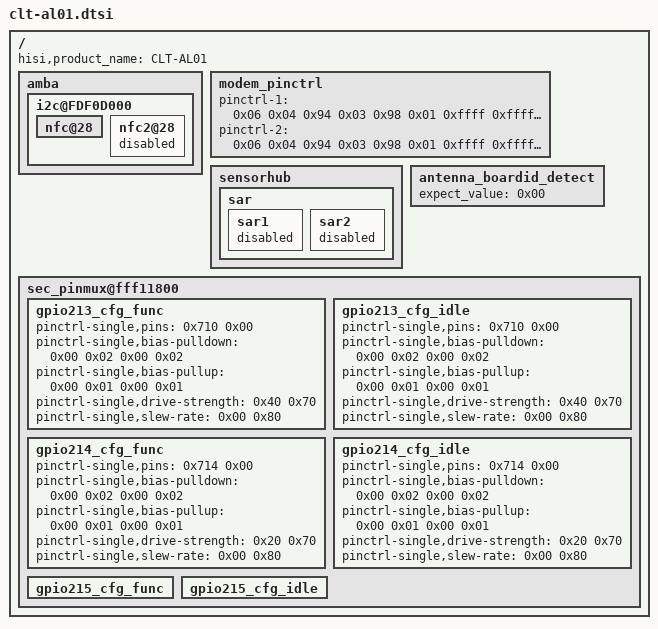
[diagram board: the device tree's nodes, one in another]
/include/ "../clt-common.dtsi"

/ {
	hisi,product_name = "CLT-AL01";

	amba {
		i2c@FDF0D000 {
			nfc@28 {
				status = "ok";
			};

			nfc2@28 {
				status = "disabled";
			};
		};
	};

	modem_pinctrl {
		pinctrl-1 = <0x06 0x04 0x94 0x03 0x98 0x01 0xffff 0xffff 0x06 0x05 0x98 0x03 0x9c 0x00 0xffff 0xffff 0x07 0x02 0xac 0x02 0xb0 0x00 0xffff 0xffff 0x07 0x03 0xb0 0x01 0xb4 0x00 0x01 0x00 0x07 0x04 0xb4 0x01 0xb8 0x00 0x01 0x00 0x07 0x05 0xb8 0x01 0xbc 0x00 0x01 0x00 0x07 0x06 0xbc 0x01 0xc0 0x00 0x01 0x00 0x07 0x07 0xc0 0x01 0xc4 0x00 0x01 0x00 0x08 0x00 0xc4 0xffff 0xc8 0xffff 0xffff 0xffff 0x08 0x01 0xc8 0xffff 0xcc 0xffff 0xffff 0xffff 0x08 0x02 0xcc 0x01 0xd0 0x00 0x01 0x00 0x08 0x03 0xd0 0x01 0xd4 0x00 0x01 0x00 0x08 0x04 0xd4 0x01 0xd8 0x00 0x01 0x00 0x08 0x05 0xd8 0x01 0xdc 0x00 0x01 0x00 0x08 0x06 0xdc 0x01 0xe0 0x00 0x01 0x00 0x08 0x07 0xe0 0x01 0xe4 0x00 0x01 0x00 0x09 0x00 0xe4 0x01 0xe8 0x00 0x01 0x00 0x09 0x01 0xe8 0x01 0xec 0x00 0x01 0x00 0x09 0x02 0xec 0x01 0xf0 0x00 0x01 0x00 0x09 0x03 0xf0 0x01 0xf4 0x00 0x01 0x00 0x09 0x04 0xf4 0x01 0xf8 0x00 0x01 0x00 0x09 0x05 0xf8 0x01 0xfc 0x00 0x01 0x00 0x09 0x06 0xfc 0x01 0x100 0x00 0x01 0x00 0x09 0x07 0x100 0x01 0x104 0x00 0x01 0x00 0x0a 0x00 0x104 0x01 0x108 0x00 0x01 0x00 0x0a 0x01 0x108 0x01 0x10c 0x00 0x01 0x00 0x0a 0x02 0x10c 0x03 0x110 0x00 0xffff 0xffff 0x0a 0x03 0x110 0x03 0x114 0x02 0xffff 0xffff 0x0a 0x04 0x114 0x01 0x118 0x00 0x01 0x00 0x0a 0x05 0x118 0x01 0x11c 0x00 0x01 0x00 0x0a 0x06 0x11c 0x01 0x120 0x00 0x01 0x00 0x0a 0x07 0x120 0x01 0x124 0x00 0x01 0x00 0x0b 0x00 0x124 0x01 0x128 0x00 0xffff 0xffff 0x0b 0x01 0x128 0x01 0x12c 0x02 0xffff 0xffff 0x0b 0x02 0x12c 0x01 0x130 0x00 0xffff 0xffff 0x0b 0x03 0x130 0x01 0x134 0x02 0xffff 0xffff 0x0b 0x04 0x134 0x01 0x138 0x00 0xffff 0xffff 0x0b 0x05 0x138 0x01 0x13c 0x02 0xffff 0xffff 0x0b 0x06 0x13c 0x01 0x140 0x00 0xffff 0xffff 0x0b 0x07 0x140 0x01 0x144 0x02 0xffff 0xffff 0x0c 0x00 0x144 0x01 0x148 0x00 0xffff 0xffff 0x12 0x05 0xac 0x03 0xdc 0x00 0xffff 0xffff 0x18 0x05 0x4c 0xffff 0x78 0xffff 0x00 0xffff>;
		pinctrl-2 = <0x06 0x04 0x94 0x03 0x98 0x01 0xffff 0xffff 0x06 0x05 0x98 0x03 0x9c 0x00 0xffff 0xffff 0x07 0x02 0xac 0x02 0xb0 0x00 0xffff 0xffff 0x07 0x03 0xb0 0x00 0xb4 0x00 0x00 0x00 0x07 0x04 0xb4 0x00 0xb8 0x00 0x00 0x00 0x07 0x05 0xb8 0x00 0xbc 0x00 0x00 0x00 0x07 0x06 0xbc 0x00 0xc0 0x00 0x00 0x00 0x07 0x07 0xc0 0x00 0xc4 0x00 0x00 0x00 0x08 0x00 0xc4 0xffff 0xc8 0xffff 0xffff 0xffff 0x08 0x01 0xc8 0xffff 0xcc 0xffff 0xffff 0xffff 0x08 0x02 0xcc 0x00 0xd0 0x00 0x00 0x00 0x08 0x03 0xd0 0x00 0xd4 0x00 0x00 0x00 0x08 0x04 0xd4 0x00 0xd8 0x00 0x00 0x00 0x08 0x05 0xd8 0x00 0xdc 0x00 0x00 0x00 0x08 0x06 0xdc 0x00 0xe0 0x00 0x00 0x00 0x08 0x07 0xe0 0x00 0xe4 0x00 0x00 0x00 0x09 0x00 0xe4 0x00 0xe8 0x00 0x00 0x00 0x09 0x01 0xe8 0x00 0xec 0x00 0x00 0x00 0x09 0x02 0xec 0x00 0xf0 0x00 0x00 0x00 0x09 0x03 0xf0 0x00 0xf4 0x00 0x00 0x00 0x09 0x04 0xf4 0x00 0xf8 0x00 0x00 0x00 0x09 0x05 0xf8 0x00 0xfc 0x00 0x00 0x00 0x09 0x06 0xfc 0x00 0x100 0x00 0x00 0x00 0x09 0x07 0x100 0x00 0x104 0x00 0x00 0x00 0x0a 0x00 0x104 0x00 0x108 0x00 0x00 0x00 0x0a 0x01 0x108 0x00 0x10c 0x00 0x00 0x00 0x0a 0x02 0x10c 0x03 0x110 0x00 0xffff 0xffff 0x0a 0x03 0x110 0x03 0x114 0x02 0xffff 0xffff 0x0a 0x04 0x114 0x00 0x118 0x00 0x00 0x00 0x0a 0x05 0x118 0x00 0x11c 0x00 0x00 0x00 0x0a 0x06 0x11c 0x00 0x120 0x00 0x00 0x00 0x0a 0x07 0x120 0x00 0x124 0x00 0x00 0x00 0x0b 0x00 0x124 0x01 0x128 0x00 0xffff 0xffff 0x0b 0x01 0x128 0x01 0x12c 0x02 0xffff 0xffff 0x0b 0x02 0x12c 0x01 0x130 0x00 0xffff 0xffff 0x0b 0x03 0x130 0x01 0x134 0x02 0xffff 0xffff 0x0b 0x04 0x134 0x00 0x138 0x02 0x00 0xffff 0x0b 0x05 0x138 0x00 0x13c 0x02 0x00 0xffff 0x0b 0x06 0x13c 0x01 0x140 0x00 0xffff 0xffff 0x0b 0x07 0x140 0x01 0x144 0x02 0xffff 0xffff 0x0c 0x00 0x144 0x01 0x148 0x00 0xffff 0xffff 0x12 0x05 0xac 0x03 0xdc 0x00 0xffff 0xffff 0x18 0x05 0x4c 0xffff 0x78 0xffff 0xffff 0xffff>;
	};

	sensorhub {
		sar {
			sar1 {
				status = "disabled";
			};

			sar2 {
				status = "disabled";
			};
		};
	};

	antenna_boardid_detect {
		expect_value = <0x00>;
	};

	sec_pinmux@fff11800 {
		gpio213_cfg_func {
			pinctrl-single,pins = <0x710 0x00>;
			pinctrl-single,bias-pulldown = <0x00 0x02 0x00 0x02>;
			pinctrl-single,bias-pullup = <0x00 0x01 0x00 0x01>;
			pinctrl-single,drive-strength = <0x40 0x70>;
			pinctrl-single,slew-rate = <0x00 0x80>;
			phandle = <0x664>;
		};

		gpio213_cfg_idle {
			pinctrl-single,pins = <0x710 0x00>;
			pinctrl-single,bias-pulldown = <0x00 0x02 0x00 0x02>;
			pinctrl-single,bias-pullup = <0x00 0x01 0x00 0x01>;
			pinctrl-single,drive-strength = <0x40 0x70>;
			pinctrl-single,slew-rate = <0x00 0x80>;
			phandle = <0x665>;
		};

		gpio214_cfg_func {
			pinctrl-single,pins = <0x714 0x00>;
			pinctrl-single,bias-pulldown = <0x00 0x02 0x00 0x02>;
			pinctrl-single,bias-pullup = <0x00 0x01 0x00 0x01>;
			pinctrl-single,drive-strength = <0x20 0x70>;
			pinctrl-single,slew-rate = <0x00 0x80>;
			phandle = <0x666>;
		};

		gpio214_cfg_idle {
			pinctrl-single,pins = <0x714 0x00>;
			pinctrl-single,bias-pulldown = <0x00 0x02 0x00 0x02>;
			pinctrl-single,bias-pullup = <0x00 0x01 0x00 0x01>;
			pinctrl-single,drive-strength = <0x20 0x70>;
			pinctrl-single,slew-rate = <0x00 0x80>;
			phandle = <0x667>;
		};

		gpio215_cfg_func {
			phandle = <0x668>;
		};

		gpio215_cfg_idle {
			phandle = <0x669>;
		};
	};

	__symbols__ {
		gpio213_cfg_func = "/sec_pinmux@fff11800/gpio213_cfg_func";
		gpio213_cfg_idle = "/sec_pinmux@fff11800/gpio213_cfg_idle";
		gpio214_cfg_func = "/sec_pinmux@fff11800/gpio214_cfg_func";
		gpio214_cfg_idle = "/sec_pinmux@fff11800/gpio214_cfg_idle";
		gpio215_cfg_func = "/sec_pinmux@fff11800/gpio215_cfg_func";
		gpio215_cfg_idle = "/sec_pinmux@fff11800/gpio215_cfg_idle";
	};
};
